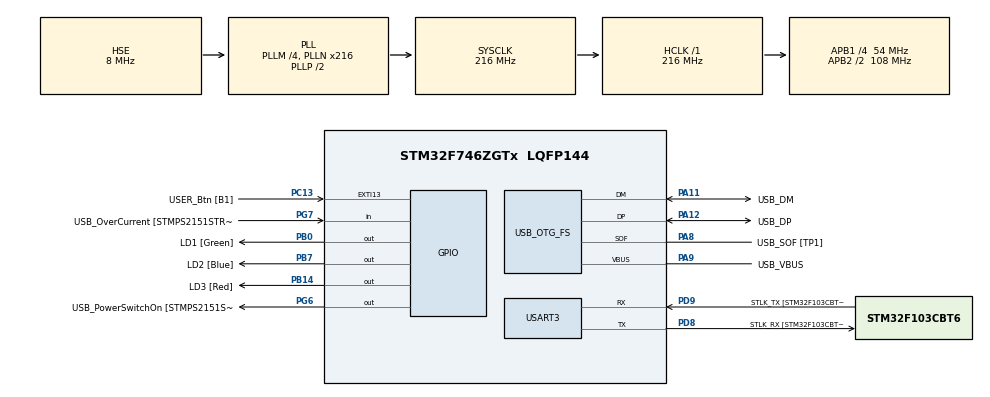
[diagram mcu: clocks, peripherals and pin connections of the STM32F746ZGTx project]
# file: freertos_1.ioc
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FREERTOS.Tasks01=defaultTask,24,128,StartDefaultTask,Default,NULL,Dynamic,NULL,NULL
Mcu.Family=STM32F7
Mcu.Name=STM32F746ZGTx
Mcu.Package=LQFP144
NVIC.PriorityGroup=NVIC_PRIORITYGROUP_4
NVIC.TIM1_UP_TIM10_IRQn=true\:0\:0\:false\:false\:true\:false\:false\:true
NVIC.TimeBase=TIM1_UP_TIM10_IRQn
NVIC.TimeBaseIP=TIM1
PA1.GPIO_Label=RMII_REF_CLK [LAN8742A-CZ-TR_REFCLK0]
PA1.Signal=ETH_REF_CLK
PA10.GPIO_Label=USB_ID
PA10.Signal=USB_OTG_FS_ID
PA11.GPIO_Label=USB_DM
PA11.Mode=Device_Only
PA11.Signal=USB_OTG_FS_DM
PA12.GPIO_Label=USB_DP
PA12.Mode=Device_Only
PA12.Signal=USB_OTG_FS_DP
PA13.GPIO_Label=TMS
PA13.Mode=Serial_Wire
PA13.Signal=SYS_JTMS-SWDIO
PA14.GPIO_Label=TCK
PA14.Mode=Serial_Wire
PA14.Signal=SYS_JTCK-SWCLK
PA2.GPIO_Label=RMII_MDIO [LAN8742A-CZ-TR_MDIO]
PA2.Signal=ETH_MDIO
PA7.GPIO_Label=RMII_CRS_DV [LAN8742A-CZ-TR_CRS_DV]
PA7.Signal=ETH_CRS_DV
PA8.GPIO_Label=USB_SOF [TP1]
PA8.Mode=Activate_SOF_FS
PA8.Signal=USB_OTG_FS_SOF
PA9.GPIO_Label=USB_VBUS
PA9.Mode=Activate_VBUS
PA9.Signal=USB_OTG_FS_VBUS
PB0.GPIO_Label=LD1 [Green]
PB0.Signal=GPIO_Output
PB13.GPIO_Label=RMII_TXD1 [LAN8742A-CZ-TR_TXD1]
PB13.Signal=ETH_TXD1
PB14.GPIO_Label=LD3 [Red]
PB14.Signal=GPIO_Output
PB3.GPIO_Label=SW0
PB3.Signal=SYS_JTDO-SWO
PB7.GPIO_Label=LD2 [Blue]
PB7.Signal=GPIO_Output
PC1.GPIO_Label=RMII_MDC [LAN8742A-CZ-TR_MDC]
PC1.Signal=ETH_MDC
PC13.GPIO_Label=USER_Btn [B1]
PC13.Signal=GPXTI13
PC14/OSC32_IN.Mode=LSE-External-Oscillator
PC14/OSC32_IN.Signal=RCC_OSC32_IN
PC15/OSC32_OUT.Mode=LSE-External-Oscillator
PC15/OSC32_OUT.Signal=RCC_OSC32_OUT
PC4.GPIO_Label=RMII_RXD0 [LAN8742A-CZ-TR_RXD0]
PC4.Signal=ETH_RXD0
PC5.GPIO_Label=RMII_RXD1 [LAN8742A-CZ-TR_RXD1]
PC5.Signal=ETH_RXD1
PD8.GPIO_Label=STLK_RX [STM32F103CBT6_PA3]
PD8.Mode=Asynchronous
PD8.Signal=USART3_TX
PD9.GPIO_Label=STLK_TX [STM32F103CBT6_PA2]
PD9.Mode=Asynchronous
PD9.Signal=USART3_RX
PG11.GPIO_Label=RMII_TX_EN [LAN8742A-CZ-TR_TXEN]
PG11.Signal=ETH_TX_EN
PG13.GPIO_Label=RMII_TXD0 [LAN8742A-CZ-TR_TXD0]
PG13.Signal=ETH_TXD0
PG6.GPIO_Label=USB_PowerSwitchOn [STMPS2151STR_EN]
PG6.Signal=GPIO_Output
PG7.GPIO_Label=USB_OverCurrent [STMPS2151STR_FAULT]
PG7.Signal=GPIO_Input
PH0/OSC_IN.GPIO_Label=MCO [STM32F103CBT6_PA8]
PH0/OSC_IN.Mode=HSE-External-Clock-Source
PH0/OSC_IN.Signal=RCC_OSC_IN
PH1/OSC_OUT.Mode=HSE-External-Clock-Source
PH1/OSC_OUT.Signal=RCC_OSC_OUT
ProjectManager.HeapSize=0x200
ProjectManager.StackSize=0x400
ProjectManager.TargetToolchain=STM32CubeIDE
RCC.48MHZClocksFreq_Value=24000000
RCC.AHBFreq_Value=216000000
RCC.APB1CLKDivider=RCC_HCLK_DIV4
RCC.APB1Freq_Value=54000000
RCC.APB1TimFreq_Value=108000000
RCC.APB2CLKDivider=RCC_HCLK_DIV2
RCC.APB2Freq_Value=108000000
RCC.APB2TimFreq_Value=216000000
RCC.CortexFreq_Value=216000000
RCC.HCLKFreq_Value=216000000
RCC.HSE_VALUE=8000000
RCC.HSI_VALUE=16000000
RCC.PLLM=4
RCC.PLLMUL=RCC_PLL_MUL9
RCC.PLLN=216
RCC.PLLQ=9
RCC.PRESCALERUSB=RCC_USBCLKSOURCE_PLL_DIV1_5
RCC.SYSCLKFreq_VALUE=216000000
RCC.SYSCLKSource=RCC_SYSCLKSOURCE_PLLCLK
RCC.SYSCLKSourceVirtual=RCC_SYSCLKSOURCE_PLLCLK
RCC.USBFreq_Value=48000000
RCC.VCOOutputFreq_Value=432000000
USART3.VirtualMode-Asynchronous=VM_ASYNC
USB_OTG_FS.VirtualMode=Device_Only
VP_FREERTOS_VS_CMSIS_V2.Mode=CMSIS_V2
VP_SYS_VS_tim1.Mode=TIM1
board=NUCLEO-F746ZG

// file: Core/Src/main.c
/* USER CODE BEGIN Header */
/**
  ******************************************************************************
  * @file           : main.c
  * @brief          : Main program body
  ******************************************************************************
  * @attention
  *
  * <h2><center>&copy; Copyright (c) 2021 STMicroelectronics.
  * All rights reserved.</center></h2>
  *
  * This software component is licensed by ST under Ultimate Liberty license
  * SLA0044, the "License"; You may not use this file except in compliance with
  * the License. You may obtain a copy of the License at:
  *                             www.st.com/SLA0044
  *
  ******************************************************************************
  */
/* USER CODE END Header */
#include "main.h"
#include "cmsis_os.h"

UART_HandleTypeDef huart3;

PCD_HandleTypeDef hpcd_USB_OTG_FS;

/* Definitions for defaultTask */
osThreadId_t defaultTaskHandle;
const osThreadAttr_t defaultTask_attributes = {
  .name = "defaultTask",
  .stack_size = 128 * 4,
  .priority = (osPriority_t) osPriorityNormal,
};

void SystemClock_Config(void);
static void MX_GPIO_Init(void);
static void MX_USART3_UART_Init(void);
static void MX_USB_OTG_FS_PCD_Init(void);
void StartDefaultTask(void *argument);
void vTask1( void *pvParameters );
void vTask2( void *pvParameters );

int main(void)
{

  /* MCU Configuration--------------------------------------------------------*/

  /* Reset of all peripherals, Initializes the Flash interface and the Systick. */
  HAL_Init();

  /* Configure the system clock */
  SystemClock_Config();

  /* Initialize all configured peripherals */
  MX_GPIO_Init();
  MX_USART3_UART_Init();
  MX_USB_OTG_FS_PCD_Init();

  /* Init scheduler */
  osKernelInitialize();

  /* Create the thread(s) */
  /* creation of defaultTask */
  defaultTaskHandle = osThreadNew(StartDefaultTask, NULL, &defaultTask_attributes);

  /* USER CODE BEGIN RTOS_THREADS */
  /* add threads, ... */
  xTaskCreate(vTask1, (signed char *) "Task1", configMINIMAL_STACK_SIZE, NULL, 1, NULL);
  xTaskCreate(vTask2, ( signed char * ) "Task2", configMINIMAL_STACK_SIZE, NULL, 1, NULL );
  /* Запустить планировщик. Задачи начнут выполняться. */
//  vTaskStartScheduler();
  /* USER CODE END RTOS_THREADS */

  /* Start scheduler */
  osKernelStart();

  /* We should never get here as control is now taken by the scheduler */
  /* Infinite loop */
  while (1)
  {

  }
}

void SystemClock_Config(void)
{
  RCC_OscInitTypeDef RCC_OscInitStruct = {0};
  RCC_ClkInitTypeDef RCC_ClkInitStruct = {0};
  RCC_PeriphCLKInitTypeDef PeriphClkInitStruct = {0};

  /** Configure LSE Drive Capability
  */
  HAL_PWR_EnableBkUpAccess();
  /** Configure the main internal regulator output voltage
  */
  __HAL_RCC_PWR_CLK_ENABLE();
  __HAL_PWR_VOLTAGESCALING_CONFIG(PWR_REGULATOR_VOLTAGE_SCALE1);
  /** Initializes the RCC Oscillators according to the specified parameters
  * in the RCC_OscInitTypeDef structure.
  */
  RCC_OscInitStruct.OscillatorType = RCC_OSCILLATORTYPE_HSE;
  RCC_OscInitStruct.HSEState = RCC_HSE_BYPASS;
  RCC_OscInitStruct.PLL.PLLState = RCC_PLL_ON;
  RCC_OscInitStruct.PLL.PLLSource = RCC_PLLSOURCE_HSE;
  RCC_OscInitStruct.PLL.PLLM = 4;
  RCC_OscInitStruct.PLL.PLLN = 216;
  RCC_OscInitStruct.PLL.PLLP = RCC_PLLP_DIV2;
  RCC_OscInitStruct.PLL.PLLQ = 9;
  if (HAL_RCC_OscConfig(&RCC_OscInitStruct) != HAL_OK)
  {
    Error_Handler();
  }
  /** Activate the Over-Drive mode
  */
  if (HAL_PWREx_EnableOverDrive() != HAL_OK)
  {
    Error_Handler();
  }
  /** Initializes the CPU, AHB and APB buses clocks
  */
  RCC_ClkInitStruct.ClockType = RCC_CLOCKTYPE_HCLK|RCC_CLOCKTYPE_SYSCLK
                              |RCC_CLOCKTYPE_PCLK1|RCC_CLOCKTYPE_PCLK2;
  RCC_ClkInitStruct.SYSCLKSource = RCC_SYSCLKSOURCE_PLLCLK;
  RCC_ClkInitStruct.AHBCLKDivider = RCC_SYSCLK_DIV1;
  RCC_ClkInitStruct.APB1CLKDivider = RCC_HCLK_DIV4;
  RCC_ClkInitStruct.APB2CLKDivider = RCC_HCLK_DIV2;

  if (HAL_RCC_ClockConfig(&RCC_ClkInitStruct, FLASH_LATENCY_7) != HAL_OK)
  {
    Error_Handler();
  }
  PeriphClkInitStruct.PeriphClockSelection = RCC_PERIPHCLK_USART3|RCC_PERIPHCLK_CLK48;
  PeriphClkInitStruct.Usart3ClockSelection = RCC_USART3CLKSOURCE_PCLK1;
  PeriphClkInitStruct.Clk48ClockSelection = RCC_CLK48SOURCE_PLL;
  if (HAL_RCCEx_PeriphCLKConfig(&PeriphClkInitStruct) != HAL_OK)
  {
    Error_Handler();
  }
}

static void MX_USART3_UART_Init(void)
{

  huart3.Instance = USART3;
  huart3.Init.BaudRate = 115200;
  huart3.Init.WordLength = UART_WORDLENGTH_8B;
  huart3.Init.StopBits = UART_STOPBITS_1;
  huart3.Init.Parity = UART_PARITY_NONE;
  huart3.Init.Mode = UART_MODE_TX_RX;
  huart3.Init.HwFlowCtl = UART_HWCONTROL_NONE;
  huart3.Init.OverSampling = UART_OVERSAMPLING_16;
  huart3.Init.OneBitSampling = UART_ONE_BIT_SAMPLE_DISABLE;
  huart3.AdvancedInit.AdvFeatureInit = UART_ADVFEATURE_NO_INIT;
  if (HAL_UART_Init(&huart3) != HAL_OK)
  {
    Error_Handler();
  }

}

static void MX_USB_OTG_FS_PCD_Init(void)
{

  hpcd_USB_OTG_FS.Instance = USB_OTG_FS;
  hpcd_USB_OTG_FS.Init.dev_endpoints = 6;
  hpcd_USB_OTG_FS.Init.speed = PCD_SPEED_FULL;
  hpcd_USB_OTG_FS.Init.dma_enable = DISABLE;
  hpcd_USB_OTG_FS.Init.phy_itface = PCD_PHY_EMBEDDED;
  hpcd_USB_OTG_FS.Init.Sof_enable = ENABLE;
  hpcd_USB_OTG_FS.Init.low_power_enable = DISABLE;
  hpcd_USB_OTG_FS.Init.lpm_enable = DISABLE;
  hpcd_USB_OTG_FS.Init.vbus_sensing_enable = ENABLE;
  hpcd_USB_OTG_FS.Init.use_dedicated_ep1 = DISABLE;
  if (HAL_PCD_Init(&hpcd_USB_OTG_FS) != HAL_OK)
  {
    Error_Handler();
  }

}

static void MX_GPIO_Init(void)
{
  GPIO_InitTypeDef GPIO_InitStruct = {0};

  /* GPIO Ports Clock Enable */
  __HAL_RCC_GPIOC_CLK_ENABLE();
  __HAL_RCC_GPIOH_CLK_ENABLE();
  __HAL_RCC_GPIOA_CLK_ENABLE();
  __HAL_RCC_GPIOB_CLK_ENABLE();
  __HAL_RCC_GPIOD_CLK_ENABLE();
  __HAL_RCC_GPIOG_CLK_ENABLE();

  /*Configure GPIO pin Output Level */
  HAL_GPIO_WritePin(GPIOB, LD1_Pin|LD3_Pin|LD2_Pin, GPIO_PIN_RESET);

  /*Configure GPIO pin Output Level */
  HAL_GPIO_WritePin(USB_PowerSwitchOn_GPIO_Port, USB_PowerSwitchOn_Pin, GPIO_PIN_RESET);

  /*Configure GPIO pin : USER_Btn_Pin */
  GPIO_InitStruct.Pin = USER_Btn_Pin;
  GPIO_InitStruct.Mode = GPIO_MODE_IT_RISING;
  GPIO_InitStruct.Pull = GPIO_NOPULL;
  HAL_GPIO_Init(USER_Btn_GPIO_Port, &GPIO_InitStruct);

  /*Configure GPIO pins : RMII_MDC_Pin RMII_RXD0_Pin RMII_RXD1_Pin */
  GPIO_InitStruct.Pin = RMII_MDC_Pin|RMII_RXD0_Pin|RMII_RXD1_Pin;
  GPIO_InitStruct.Mode = GPIO_MODE_AF_PP;
  GPIO_InitStruct.Pull = GPIO_NOPULL;
  GPIO_InitStruct.Speed = GPIO_SPEED_FREQ_VERY_HIGH;
  GPIO_InitStruct.Alternate = GPIO_AF11_ETH;
  HAL_GPIO_Init(GPIOC, &GPIO_InitStruct);

  /*Configure GPIO pins : RMII_REF_CLK_Pin RMII_MDIO_Pin RMII_CRS_DV_Pin */
  GPIO_InitStruct.Pin = RMII_REF_CLK_Pin|RMII_MDIO_Pin|RMII_CRS_DV_Pin;
  GPIO_InitStruct.Mode = GPIO_MODE_AF_PP;
  GPIO_InitStruct.Pull = GPIO_NOPULL;
  GPIO_InitStruct.Speed = GPIO_SPEED_FREQ_VERY_HIGH;
  GPIO_InitStruct.Alternate = GPIO_AF11_ETH;
  HAL_GPIO_Init(GPIOA, &GPIO_InitStruct);

  /*Configure GPIO pins : LD1_Pin LD3_Pin LD2_Pin */
  GPIO_InitStruct.Pin = LD1_Pin|LD3_Pin|LD2_Pin;
  GPIO_InitStruct.Mode = GPIO_MODE_OUTPUT_PP;
  GPIO_InitStruct.Pull = GPIO_NOPULL;
  GPIO_InitStruct.Speed = GPIO_SPEED_FREQ_LOW;
  HAL_GPIO_Init(GPIOB, &GPIO_InitStruct);

  /*Configure GPIO pin : RMII_TXD1_Pin */
  GPIO_InitStruct.Pin = RMII_TXD1_Pin;
  GPIO_InitStruct.Mode = GPIO_MODE_AF_PP;
  GPIO_InitStruct.Pull = GPIO_NOPULL;
  GPIO_InitStruct.Speed = GPIO_SPEED_FREQ_VERY_HIGH;
  GPIO_InitStruct.Alternate = GPIO_AF11_ETH;
  HAL_GPIO_Init(RMII_TXD1_GPIO_Port, &GPIO_InitStruct);

  /*Configure GPIO pin : USB_PowerSwitchOn_Pin */
  GPIO_InitStruct.Pin = USB_PowerSwitchOn_Pin;
  GPIO_InitStruct.Mode = GPIO_MODE_OUTPUT_PP;
  GPIO_InitStruct.Pull = GPIO_NOPULL;
  GPIO_InitStruct.Speed = GPIO_SPEED_FREQ_LOW;
  HAL_GPIO_Init(USB_PowerSwitchOn_GPIO_Port, &GPIO_InitStruct);

  /*Configure GPIO pin : USB_OverCurrent_Pin */
  GPIO_InitStruct.Pin = USB_OverCurrent_Pin;
  GPIO_InitStruct.Mode = GPIO_MODE_INPUT;
  GPIO_InitStruct.Pull = GPIO_NOPULL;
  HAL_GPIO_Init(USB_OverCurrent_GPIO_Port, &GPIO_InitStruct);

  /*Configure GPIO pins : RMII_TX_EN_Pin RMII_TXD0_Pin */
  GPIO_InitStruct.Pin = RMII_TX_EN_Pin|RMII_TXD0_Pin;
  GPIO_InitStruct.Mode = GPIO_MODE_AF_PP;
  GPIO_InitStruct.Pull = GPIO_NOPULL;
  GPIO_InitStruct.Speed = GPIO_SPEED_FREQ_VERY_HIGH;
  GPIO_InitStruct.Alternate = GPIO_AF11_ETH;
  HAL_GPIO_Init(GPIOG, &GPIO_InitStruct);

}

/* USER CODE BEGIN 4 */
void vTask1( void *pvParameters )
{
	/* Квалификатор volatile запрещает оптимизацию
	/* переменной ul */
	volatile unsigned long ul;
	/* Как и большинство задач, эта задача содержит
	/* бесконечный цикл */
	for( ;; ){

		HAL_GPIO_TogglePin(LD1_GPIO_Port, LD1_Pin);
		osDelay(1000);
	}
	/* Уничтожить задачу, если произошел выход
	/* из бесконечного цикла (в данной реализации выход
	/* заведомо не произойдет) */
	vTaskDelete( NULL );
}

void vTask2( void *pvParameters )
{
	volatile unsigned long ul;
	for( ;; ){
		HAL_GPIO_TogglePin(LD2_GPIO_Port, LD2_Pin);
		osDelay(1000);

	}
	vTaskDelete( NULL );
}
/* USER CODE END 4 */

void StartDefaultTask(void *argument)
{
  for(;;)
  {
    osDelay(1);
  }
}

 /**
  * @brief  Period elapsed callback in non blocking mode
  * @note   This function is called  when TIM1 interrupt took place, inside
  * HAL_TIM_IRQHandler(). It makes a direct call to HAL_IncTick() to increment
  * a global variable "uwTick" used as application time base.
  * @param  htim : TIM handle
  * @retval None
  */
void HAL_TIM_PeriodElapsedCallback(TIM_HandleTypeDef *htim)
{
  if (htim->Instance == TIM1) {
    HAL_IncTick();
  }
}

void Error_Handler(void)
{
  __disable_irq();
  while (1)
  {
  }
}

/************************ (C) COPYRIGHT STMicroelectronics *****END OF FILE****/
